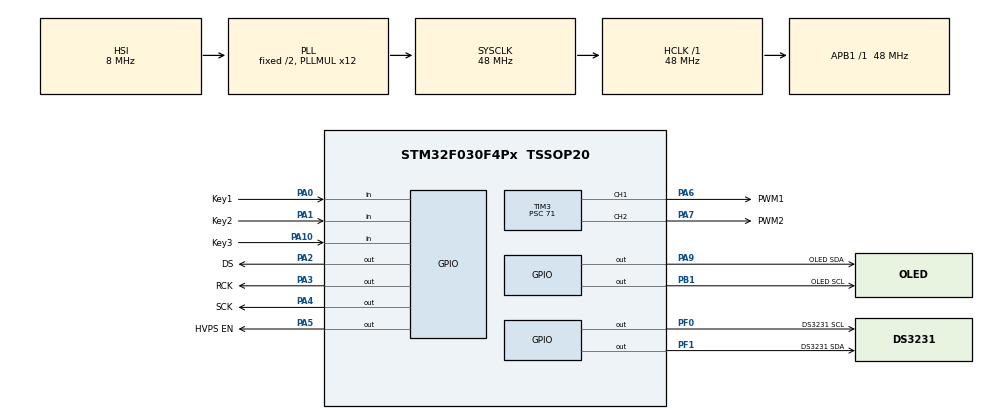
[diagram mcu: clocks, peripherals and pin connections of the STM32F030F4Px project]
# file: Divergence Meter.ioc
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Mcu.Family=STM32F0
Mcu.Name=STM32F030F4Px
Mcu.Package=TSSOP20
NVIC.TIM14_IRQn=true\:0\:0\:false\:false\:true\:true
PA0.GPIO_Label=Key1
PA0.Signal=GPIO_Input
PA1.GPIO_Label=Key2
PA1.Signal=GPIO_Input
PA10.GPIO_Label=Key3
PA10.GPIO_Mode=GPIO_MODE_INPUT
PA10.GPIO_PuPd=GPIO_PULLUP
PA10.Signal=GPIO_Input
PA2.GPIO_Label=DS
PA2.GPIO_ModeDefaultOutputPP=GPIO_MODE_OUTPUT_PP
PA2.GPIO_PuPd=GPIO_NOPULL
PA2.GPIO_Speed=GPIO_SPEED_FREQ_HIGH
PA2.PinState=GPIO_PIN_RESET
PA2.Signal=GPIO_Output
PA3.GPIO_Label=RCK
PA3.GPIO_ModeDefaultOutputPP=GPIO_MODE_OUTPUT_PP
PA3.GPIO_PuPd=GPIO_NOPULL
PA3.GPIO_Speed=GPIO_SPEED_FREQ_HIGH
PA3.PinState=GPIO_PIN_RESET
PA3.Signal=GPIO_Output
PA4.GPIO_Label=SCK
PA4.GPIO_ModeDefaultOutputPP=GPIO_MODE_OUTPUT_PP
PA4.GPIO_PuPd=GPIO_NOPULL
PA4.GPIO_Speed=GPIO_SPEED_FREQ_HIGH
PA4.PinState=GPIO_PIN_RESET
PA4.Signal=GPIO_Output
PA5.GPIO_Label=HVPS EN
PA5.GPIO_ModeDefaultOutputPP=GPIO_MODE_OUTPUT_PP
PA5.GPIO_PuPd=GPIO_NOPULL
PA5.GPIO_Speed=GPIO_SPEED_FREQ_HIGH
PA5.PinState=GPIO_PIN_RESET
PA5.Signal=GPIO_Output
PA6.GPIO_Label=PWM1
PA6.GPIO_Speed=GPIO_SPEED_FREQ_HIGH
PA6.Signal=S_TIM3_CH1
PA7.GPIO_Label=PWM2
PA7.GPIO_Speed=GPIO_SPEED_FREQ_HIGH
PA7.Signal=S_TIM3_CH2
PA9.GPIO_Label=OLED SDA
PA9.GPIO_ModeDefaultOutputPP=GPIO_MODE_OUTPUT_PP
PA9.GPIO_PuPd=GPIO_NOPULL
PA9.GPIO_Speed=GPIO_SPEED_FREQ_HIGH
PA9.PinState=GPIO_PIN_RESET
PA9.Signal=GPIO_Output
PB1.GPIO_Label=OLED SCL
PB1.GPIO_ModeDefaultOutputPP=GPIO_MODE_OUTPUT_PP
PB1.GPIO_PuPd=GPIO_NOPULL
PB1.GPIO_Speed=GPIO_SPEED_FREQ_HIGH
PB1.PinState=GPIO_PIN_RESET
PB1.Signal=GPIO_Output
PF0-OSC_IN.GPIO_Label=DS3231 SCL
PF0-OSC_IN.GPIO_ModeDefaultOutputPP=GPIO_MODE_OUTPUT_PP
PF0-OSC_IN.GPIO_PuPd=GPIO_NOPULL
PF0-OSC_IN.GPIO_Speed=GPIO_SPEED_FREQ_HIGH
PF0-OSC_IN.PinState=GPIO_PIN_RESET
PF0-OSC_IN.Signal=GPIO_Output
PF1-OSC_OUT.GPIO_Label=DS3231 SDA
PF1-OSC_OUT.GPIO_ModeDefaultOutputPP=GPIO_MODE_OUTPUT_PP
PF1-OSC_OUT.GPIO_PuPd=GPIO_NOPULL
PF1-OSC_OUT.GPIO_Speed=GPIO_SPEED_FREQ_HIGH
PF1-OSC_OUT.PinState=GPIO_PIN_RESET
PF1-OSC_OUT.Signal=GPIO_Output
ProjectManager.HeapSize=0x200
ProjectManager.StackSize=0x400
ProjectManager.TargetToolchain=MDK-ARM V5
RCC.AHBFreq_Value=48000000
RCC.APB1Freq_Value=48000000
RCC.APB1TimFreq_Value=48000000
RCC.HCLKFreq_Value=48000000
RCC.PLLMUL=RCC_PLL_MUL12
RCC.SYSCLKFreq_VALUE=48000000
RCC.SYSCLKSource=RCC_SYSCLKSOURCE_PLLCLK
SH.S_TIM3_CH1.0=TIM3_CH1,PWM Generation1 CH1
SH.S_TIM3_CH2.0=TIM3_CH2,PWM Generation2 CH2
TIM14.Period=999
TIM14.Prescaler=71
TIM3.Channel-PWM\ Generation1\ CH1=TIM_CHANNEL_1
TIM3.Channel-PWM\ Generation2\ CH2=TIM_CHANNEL_2
TIM3.Period=999
TIM3.Prescaler=71
VP_TIM14_VS_ClockSourceINT.Mode=Enable_Timer
VP_TIM3_VS_ClockSourceINT.Mode=Internal
board=custom

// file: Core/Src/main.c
/**
  ******************************************************************************
  * @file           : main.c
  * @brief          : Main program body
  ******************************************************************************
  ** This notice applies to any and all portions of this file
  * that are not between comment pairs USER CODE BEGIN and
  * USER CODE END. Other portions of this file, whether
  * inserted by the user or by software development tools
  * are owned by their respective copyright owners.
  *
  * COPYRIGHT(c) 2019 STMicroelectronics
  *
  * Redistribution and use in source and binary forms, with or without modification,
  * are permitted provided that the following conditions are met:
  *   1. Redistributions of source code must retain the above copyright notice,
  *      this list of conditions and the following disclaimer.
  *   2. Redistributions in binary form must reproduce the above copyright notice,
  *      this list of conditions and the following disclaimer in the documentation
  *      and/or other materials provided with the distribution.
  *   3. Neither the name of STMicroelectronics nor the names of its contributors
  *      may be used to endorse or promote products derived from this software
  *      without specific prior written permission.
  *
  * THIS SOFTWARE IS PROVIDED BY THE COPYRIGHT HOLDERS AND CONTRIBUTORS "AS IS"
  * AND ANY EXPRESS OR IMPLIED WARRANTIES, INCLUDING, BUT NOT LIMITED TO, THE
  * IMPLIED WARRANTIES OF MERCHANTABILITY AND FITNESS FOR A PARTICULAR PURPOSE ARE
  * DISCLAIMED. IN NO EVENT SHALL THE COPYRIGHT HOLDER OR CONTRIBUTORS BE LIABLE
  * FOR ANY DIRECT, INDIRECT, INCIDENTAL, SPECIAL, EXEMPLARY, OR CONSEQUENTIAL
  * DAMAGES (INCLUDING, BUT NOT LIMITED TO, PROCUREMENT OF SUBSTITUTE GOODS OR
  * SERVICES; LOSS OF USE, DATA, OR PROFITS; OR BUSINESS INTERRUPTION) HOWEVER
  * CAUSED AND ON ANY THEORY OF LIABILITY, WHETHER IN CONTRACT, STRICT LIABILITY,
  * OR TORT (INCLUDING NEGLIGENCE OR OTHERWISE) ARISING IN ANY WAY OUT OF THE USE
  * OF THIS SOFTWARE, EVEN IF ADVISED OF THE POSSIBILITY OF SUCH DAMAGE.
  *
  ******************************************************************************
  */
#include "main.h"
#include "stm32f0xx_hal.h"

/* USER CODE BEGIN Includes */
#include "AmadeusMain.h"
/* USER CODE END Includes */

TIM_HandleTypeDef htim3;
TIM_HandleTypeDef htim14;

/* USER CODE BEGIN PV */
/* Private variables ---------------------------------------------------------*/

/* USER CODE END PV */

void SystemClock_Config(void);
static void MX_GPIO_Init(void);
static void MX_TIM3_Init(void);
static void MX_TIM14_Init(void);
void HAL_TIM_MspPostInit(TIM_HandleTypeDef *htim);

/* USER CODE BEGIN PFP */
/* Private function prototypes -----------------------------------------------*/

/* USER CODE END PFP */

int main(void)
{

  /* MCU Configuration----------------------------------------------------------*/

  /* Reset of all peripherals, Initializes the Flash interface and the Systick. */
  HAL_Init();

  /* Configure the system clock */
  SystemClock_Config();

  /* Initialize all configured peripherals */
  MX_GPIO_Init();
  MX_TIM3_Init();
	MX_TIM14_Init();
  /* USER CODE BEGIN 2 */
	Sys_setup();
  /* USER CODE END 2 */

  /* Infinite loop */
  while (1)
  {
		Sys_loop();
  }

}

void SystemClock_Config(void)
{

  RCC_OscInitTypeDef RCC_OscInitStruct;
  RCC_ClkInitTypeDef RCC_ClkInitStruct;

    /**Initializes the CPU, AHB and APB busses clocks
    */
  RCC_OscInitStruct.OscillatorType = RCC_OSCILLATORTYPE_HSI;
  RCC_OscInitStruct.HSIState = RCC_HSI_ON;
  RCC_OscInitStruct.HSICalibrationValue = 16;
  RCC_OscInitStruct.PLL.PLLState = RCC_PLL_ON;
  RCC_OscInitStruct.PLL.PLLSource = RCC_PLLSOURCE_HSI;
  RCC_OscInitStruct.PLL.PLLMUL = RCC_PLL_MUL12;
  RCC_OscInitStruct.PLL.PREDIV = RCC_PREDIV_DIV1;
  if (HAL_RCC_OscConfig(&RCC_OscInitStruct) != HAL_OK)
  {
    _Error_Handler(__FILE__, __LINE__);
  }

    /**Initializes the CPU, AHB and APB busses clocks
    */
  RCC_ClkInitStruct.ClockType = RCC_CLOCKTYPE_HCLK|RCC_CLOCKTYPE_SYSCLK
                              |RCC_CLOCKTYPE_PCLK1;
  RCC_ClkInitStruct.SYSCLKSource = RCC_SYSCLKSOURCE_PLLCLK;
  RCC_ClkInitStruct.AHBCLKDivider = RCC_SYSCLK_DIV1;
  RCC_ClkInitStruct.APB1CLKDivider = RCC_HCLK_DIV1;

  if (HAL_RCC_ClockConfig(&RCC_ClkInitStruct, FLASH_LATENCY_1) != HAL_OK)
  {
    _Error_Handler(__FILE__, __LINE__);
  }

    /**Configure the Systick interrupt time
    */
  HAL_SYSTICK_Config(HAL_RCC_GetHCLKFreq()/1000);

    /**Configure the Systick
    */
  HAL_SYSTICK_CLKSourceConfig(SYSTICK_CLKSOURCE_HCLK);

  /* SysTick_IRQn interrupt configuration */
  HAL_NVIC_SetPriority(SysTick_IRQn, 0, 0);
}

/* TIM3 init function */
static void MX_TIM3_Init(void)
{

  TIM_ClockConfigTypeDef sClockSourceConfig;
  TIM_MasterConfigTypeDef sMasterConfig;
  TIM_OC_InitTypeDef sConfigOC;

  htim3.Instance = TIM3;
  htim3.Init.Prescaler = 47;
  htim3.Init.CounterMode = TIM_COUNTERMODE_UP;
  htim3.Init.Period = 999;
  htim3.Init.ClockDivision = TIM_CLOCKDIVISION_DIV1;
  htim3.Init.AutoReloadPreload = TIM_AUTORELOAD_PRELOAD_DISABLE;
  if (HAL_TIM_Base_Init(&htim3) != HAL_OK)
  {
    _Error_Handler(__FILE__, __LINE__);
  }

  sClockSourceConfig.ClockSource = TIM_CLOCKSOURCE_INTERNAL;
  if (HAL_TIM_ConfigClockSource(&htim3, &sClockSourceConfig) != HAL_OK)
  {
    _Error_Handler(__FILE__, __LINE__);
  }

  if (HAL_TIM_OC_Init(&htim3) != HAL_OK)
  {
    _Error_Handler(__FILE__, __LINE__);
  }

  sMasterConfig.MasterOutputTrigger = TIM_TRGO_RESET;
  sMasterConfig.MasterSlaveMode = TIM_MASTERSLAVEMODE_DISABLE;
  if (HAL_TIMEx_MasterConfigSynchronization(&htim3, &sMasterConfig) != HAL_OK)
  {
    _Error_Handler(__FILE__, __LINE__);
  }

  sConfigOC.OCMode = TIM_OCMODE_PWM1;
  sConfigOC.Pulse = 0;
  sConfigOC.OCPolarity = TIM_OCPOLARITY_HIGH;
  sConfigOC.OCFastMode = TIM_OCFAST_DISABLE;
  if (HAL_TIM_OC_ConfigChannel(&htim3, &sConfigOC, TIM_CHANNEL_1) != HAL_OK)
  {
    _Error_Handler(__FILE__, __LINE__);
  }

  if (HAL_TIM_OC_ConfigChannel(&htim3, &sConfigOC, TIM_CHANNEL_2) != HAL_OK)
  {
    _Error_Handler(__FILE__, __LINE__);
  }

  HAL_TIM_MspPostInit(&htim3);

}

/* TIM14 init function */
static void MX_TIM14_Init(void)
{

  htim14.Instance = TIM14;
  htim14.Init.Prescaler = 47;
  htim14.Init.CounterMode = TIM_COUNTERMODE_UP;
  htim14.Init.Period = 999;
  htim14.Init.ClockDivision = TIM_CLOCKDIVISION_DIV1;
  htim14.Init.AutoReloadPreload = TIM_AUTORELOAD_PRELOAD_DISABLE;
  if (HAL_TIM_Base_Init(&htim14) != HAL_OK)
  {
    _Error_Handler(__FILE__, __LINE__);
  }

}

/** Configure pins as
        * Analog
        * Input
        * Output
        * EVENT_OUT
        * EXTI
*/
static void MX_GPIO_Init(void)
{

  GPIO_InitTypeDef GPIO_InitStruct;

  /* GPIO Ports Clock Enable */
  __HAL_RCC_GPIOF_CLK_ENABLE();
  __HAL_RCC_GPIOA_CLK_ENABLE();
  __HAL_RCC_GPIOB_CLK_ENABLE();

  /*Configure GPIO pin Output Level */
  HAL_GPIO_WritePin(GPIOF, DS3231_SCL_Pin|DS3231_SDA_Pin, GPIO_PIN_RESET);

  /*Configure GPIO pin Output Level */
  HAL_GPIO_WritePin(GPIOA, DS_Pin|RCK_Pin|SCK_Pin, GPIO_PIN_RESET);

  HAL_GPIO_WritePin(GPIOA,HVPS_EN_Pin|OLED_SDA_Pin,GPIO_PIN_SET);

  /*Configure GPIO pin Output Level */
  HAL_GPIO_WritePin(OLED_SCL_GPIO_Port, OLED_SCL_Pin, GPIO_PIN_SET);

  /*Configure GPIO pins : DS3231_SCL_Pin DS3231_SDA_Pin */
  GPIO_InitStruct.Pin = DS3231_SCL_Pin|DS3231_SDA_Pin;
  GPIO_InitStruct.Mode = GPIO_MODE_OUTPUT_PP;
  GPIO_InitStruct.Pull = GPIO_NOPULL;
  GPIO_InitStruct.Speed = GPIO_SPEED_FREQ_HIGH;
  HAL_GPIO_Init(GPIOF, &GPIO_InitStruct);

  /*Configure GPIO pins : Key1_Pin Key2_Pin */
  GPIO_InitStruct.Pin = Key1_Pin|Key2_Pin;
  GPIO_InitStruct.Mode = GPIO_MODE_INPUT;
  GPIO_InitStruct.Pull = GPIO_PULLUP;
  HAL_GPIO_Init(GPIOA, &GPIO_InitStruct);

  /*Configure GPIO pins : DS_Pin RCK_Pin SCK_Pin HVPS_EN_Pin
                           OLED_SDA_Pin */
  GPIO_InitStruct.Pin = DS_Pin|RCK_Pin|SCK_Pin|HVPS_EN_Pin
                          |OLED_SDA_Pin;
  GPIO_InitStruct.Mode = GPIO_MODE_OUTPUT_PP;
  GPIO_InitStruct.Pull = GPIO_NOPULL;
  GPIO_InitStruct.Speed = GPIO_SPEED_FREQ_HIGH;
  HAL_GPIO_Init(GPIOA, &GPIO_InitStruct);

  /*Configure GPIO pin : OLED_SCL_Pin */
  GPIO_InitStruct.Pin = OLED_SCL_Pin;
  GPIO_InitStruct.Mode = GPIO_MODE_OUTPUT_PP;
  GPIO_InitStruct.Pull = GPIO_NOPULL;
  GPIO_InitStruct.Speed = GPIO_SPEED_FREQ_HIGH;
  HAL_GPIO_Init(OLED_SCL_GPIO_Port, &GPIO_InitStruct);

  /*Configure GPIO pin : Key3_Pin */
  GPIO_InitStruct.Pin = Key3_Pin;
  GPIO_InitStruct.Mode = GPIO_MODE_INPUT;
  GPIO_InitStruct.Pull = GPIO_PULLUP;
  HAL_GPIO_Init(Key3_GPIO_Port, &GPIO_InitStruct);

}

void _Error_Handler(char *file, int line)
{
  while(1)
  {
  }
}

/************************ (C) COPYRIGHT STMicroelectronics *****END OF FILE****/
